# apollo3 register map
Vendor: Ambiq Micro; Series: Apollo; File version: 1.0
CPU: CM4 r1p0, little endian, MPU, FPU, 3 interrupt priority bits
Registers are 32-bit, read-write, reset 0x0 unless marked. A register's access mark holds for its fields unless they carry their own. Offsets are from the block's base; [hi:lo] are bit positions; {n}, {i} and the like mark numbered series; 'fields as' and 'values as' point back to an identical list.

## CTIMER (part 2 of 3) — Counter/Timer
Base 0x40008000
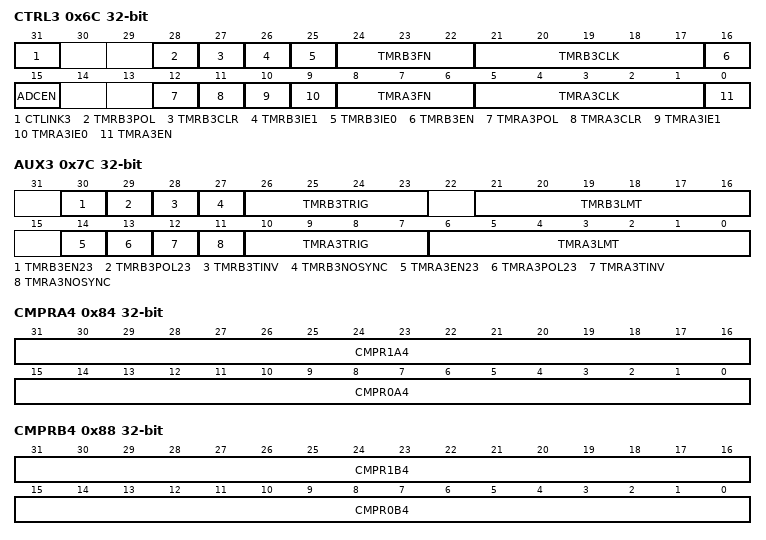
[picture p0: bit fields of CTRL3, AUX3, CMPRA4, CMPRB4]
0x6C CTRL3 — Counter/Timer Control
  [31] CTLINK3 — Counter/Timer A3/B3 Link bit.
    0=TWO_16BIT_TIMERS (Use A3/B3 timers as two independent 16-bit timers (default). value.); 1=32BIT_TIMER (Link A3/B3 timers into a single 32-bit timer. value.)
  [28] TMRB3POL — Counter/Timer B3 output polarity.
    0=NORMAL (The polarity of the TMRPINB3 pin is the same as the timer output. value.); 1=INVERTED (The polarity of the TMRPINB3 pin is the inverse of the timer output. value.)
  [27] TMRB3CLR — Counter/Timer B3 Clear bit.
    0=RUN (Allow counter/timer B3 to run value.); 1=CLEAR (Holds counter/timer B3 at 0x0000. value.)
  [26] TMRB3IE1 — Counter/Timer B3 Interrupt Enable bit for COMPR1.
    0=DIS (Disable counter/timer B3 from generating an interrupt based on COMPR1. value.); 1=EN (Enable counter/timer B3 to generate an interrupt based on COMPR1. value.)
  [25] TMRB3IE0 — Counter/Timer B3 Interrupt Enable bit for COMPR0.
    0=DIS (Disable counter/timer B3 from generating an interrupt based on COMPR0. value.); 1=EN (Enable counter/timer B3 to generate an interrupt based on COMPR0 value.)
  [24:22] TMRB3FN — Counter/Timer B3 Function Select.
    0=SINGLECOUNT (Single count (output toggles and sticks). Count to CMPR0B3, stop. value.); 1=REPEATEDCOUNT (Repeated count (periodic 1-clock-cycle-wide pulses). Count to CMPR0B3, restart. value.); 2=PULSE_ONCE (Pulse once (aka one-shot). Count to CMPR0B3, assert, count to CMPR1B3, deassert, stop. value.); 3=PULSE_CONT (Pulse continously. Count to CMPR0B3, assert, count to CMPR1B3, deassert, restart. value.); 4=SINGLEPATTERN (Single pattern. value.); 5=REPEATPATTERN (Repeated pattern. value.); 6=CONTINUOUS (Continuous run (aka Free Run). Count continuously. value.); 7=ALTPWN (Alternate PWM value.)
  [21:17] TMRB3CLK — Counter/Timer B3 Clock Select.
    0=TMRPIN (Clock source is TMRPINB. value.); 1=HFRC_DIV4 (Clock source is the HFRC / 4 value.); 2=HFRC_DIV16 (Clock source is HFRC / 16 value.); 3=HFRC_DIV256 (Clock source is HFRC / 256 value.); 4=HFRC_DIV1024 (Clock source is HFRC / 1024 value.); 5=HFRC_DIV4K (Clock source is HFRC / 4096 value.); 6=XT (Clock source is the XT (uncalibrated). value.); 7=XT_DIV2 (Clock source is XT / 2 value.); 8=XT_DIV16 (Clock source is XT / 16 value.); 9=XT_DIV128 (Clock source is XT / 128 value.); 10=LFRC_DIV2 (Clock source is LFRC / 2 value.); 11=LFRC_DIV32 (Clock source is LFRC / 32 value.); 12=LFRC_DIV1K (Clock source is LFRC / 1024 value.); 13=LFRC (Clock source is LFRC value.); 14=RTC_100HZ (Clock source is 100 Hz from the current RTC oscillator. value.); 15=HCLK (Clock source is HCLK. value.); 16=XT_DIV4 (Clock source is XT / 4 value.); 17=XT_DIV8 (Clock source is XT / 8 value.); 18=XT_DIV32 (Clock source is XT / 32 value.); 20=CTMRA3 (Clock source is CTIMERA3 OUT. value.); 21=CTMRA2 (Clock source is CTIMERA2 OUT. value.); 22=CTMRB2 (Clock source is CTIMERB2 OUT. value.); 23=CTMRA4 (Clock source is CTIMERA4 OUT. value.); 24=CTMRB4 (Clock source is CTIMERB4 OUT. value.); 25=CTMRB0 (Clock source is CTIMERB0 OUT. value.); 26=CTMRB1 (Clock source is CTIMERB1 OUT. value.); 27=CTMRB5 (Clock source is CTIMERB5 OUT. value.); 28=CTMRB6 (Clock source is CTIMERB6 OUT. value.); 29=BUCKBLE (Clock source is BLE buck converter TON pulses. value.); 30=BUCKB (Clock source is Memory buck converter TON pulses. value.); 31=BUCKA (Clock source is CPU buck converter TON pulses. value.)
  [16] TMRB3EN — Counter/Timer B3 Enable bit.
    0=DIS (Counter/Timer B3 Disable. value.); 1=EN (Counter/Timer B3 Enable. value.)
  [15] ADCEN — Special Timer A3 enable for ADC function.
  [12] TMRA3POL — Counter/Timer A3 output polarity.
    0=NORMAL (The polarity of the TMRPINA3 pin is the same as the timer output. value.); 1=INVERTED (The polarity of the TMRPINA3 pin is the inverse of the timer output. value.)
  [11] TMRA3CLR — Counter/Timer A3 Clear bit.
    0=RUN (Allow counter/timer A3 to run value.); 1=CLEAR (Holds counter/timer A3 at 0x0000. value.)
  [10] TMRA3IE1 — Counter/Timer A3 Interrupt Enable bit based on COMPR1.
    0=DIS (Disable counter/timer A3 from generating an interrupt based on COMPR1. value.); 1=EN (Enable counter/timer A3 to generate an interrupt based on COMPR1. value.)
  [9] TMRA3IE0 — Counter/Timer A3 Interrupt Enable bit based on COMPR0.
    0=DIS (Disable counter/timer A3 from generating an interrupt based on COMPR0. value.); 1=EN (Enable counter/timer A3 to generate an interrupt based on COMPR0. value.)
  [8:6] TMRA3FN — Counter/Timer A3 Function Select.
    0=SINGLECOUNT (Single count (output toggles and sticks). Count to CMPR0A3, stop. value.); 1=REPEATEDCOUNT (Repeated count (periodic 1-clock-cycle-wide pulses). Count to CMPR0A3, restart. value.); 2=PULSE_ONCE (Pulse once (aka one-shot). Count to CMPR0A3, assert, count to CMPR1A3, deassert, stop. value.); 3=PULSE_CONT (Pulse continously. Count to CMPR0A3, assert, count to CMPR1A3, deassert, restart. value.); 4=SINGLEPATTERN (Single pattern. value.); 5=REPEATPATTERN (Repeated pattern. value.); 6=CONTINUOUS (Continuous run (aka Free Run). Count continuously. value.); 7=ALTPWN (Alternate PWM value.)
  [5:1] TMRA3CLK — Counter/Timer A3 Clock Select.
    0=TMRPIN (Clock source is TMRPINA. value.); 1=HFRC_DIV4 (Clock source is the HFRC / 4 value.); 2=HFRC_DIV16 (Clock source is HFRC / 16 value.); 3=HFRC_DIV256 (Clock source is HFRC / 256 value.); 4=HFRC_DIV1024 (Clock source is HFRC / 1024 value.); 5=HFRC_DIV4K (Clock source is HFRC / 4096 value.); 6=XT (Clock source is the XT (uncalibrated). value.); 7=XT_DIV2 (Clock source is XT / 2 value.); 8=XT_DIV16 (Clock source is XT / 16 value.); 9=XT_DIV128 (Clock source is XT / 128 value.); 10=LFRC_DIV2 (Clock source is LFRC / 2 value.); 11=LFRC_DIV32 (Clock source is LFRC / 32 value.); 12=LFRC_DIV1K (Clock source is LFRC / 1024 value.); 13=LFRC (Clock source is LFRC value.); 14=RTC_100HZ (Clock source is 100 Hz from the current RTC oscillator. value.); 15=HCLK (Clock source is HCLK. value.); 16=XT_DIV4 (Clock source is XT / 4 value.); 17=XT_DIV8 (Clock source is XT / 8 value.); 18=XT_DIV32 (Clock source is XT / 32 value.); 20=CTMRB3 (Clock source is CTIMERB3 OUT. value.); 21=CTMRA2 (Clock source is CTIMERA2 OUT. value.); 22=CTMRB2 (Clock source is CTIMERB2 OUT. value.); 23=CTMRA4 (Clock source is CTIMERA4 OUT. value.); 24=CTMRB4 (Clock source is CTIMERB4 OUT. value.); 25=CTMRB0 (Clock source is CTIMERB0 OUT. value.); 26=CTMRB1 (Clock source is CTIMERB1 OUT. value.); 27=CTMRB5 (Clock source is CTIMERB5 OUT. value.); 28=CTMRB6 (Clock source is CTIMERB6 OUT. value.); 29=BUCKBLE (Clock source is BLE buck converter TON pulses. value.); 30=BUCKB (Clock source is Memory buck converter TON pulses. value.); 31=BUCKA (Clock source is CPU buck converter TON pulses. value.)
  [0] TMRA3EN — Counter/Timer A3 Enable bit.
    0=DIS (Counter/Timer A3 Disable. value.); 1=EN (Counter/Timer A3 Enable. value.)
0x7C AUX3 — Counter/Timer Auxiliary
  [30] TMRB3EN23 — Counter/Timer B3 Upper compare enable.
    1=DIS (Disable enhanced functions. value.); 0=EN (Enable enhanced functions. value.)
  [29] TMRB3POL23 — Upper output polarity
    0=NORM (Upper output normal polarity value.); 1=INV (Upper output inverted polarity. value.)
  [28] TMRB3TINV — Counter/Timer B3 Invert on trigger.
    0=DIS (Disable invert on trigger value.); 1=EN (Enable invert on trigger value.)
  [27] TMRB3NOSYNC — Source clock synchronization control.
    0=DIS (Synchronization on source clock value.); 1=NOSYNC (No synchronization on source clock value.)
  [26:23] TMRB3TRIG — Counter/Timer B3 Trigger Select.
    0=DIS (Trigger source is disabled. value.); 1=A3OUT (Trigger source is CTIMERA3 OUT. value.); 2=B2OUT (Trigger source is CTIMERB2 OUT. value.); 3=A2OUT (Trigger source is CTIMERA2 OUT. value.); 4=A4OUT (Trigger source is CTIMERA4 OUT. value.); 5=B4OUT (Trigger source is CTIMERB4 OUT. value.); 6=A6OUT (Trigger source is CTIMERA6 OUT. value.); 7=B6OUT (Trigger source is CTIMERB6 OUT. value.); 8=B5OUT2 (Trigger source is CTIMERB5 OUT2. value.); 9=A5OUT2 (Trigger source is CTIMERA5 OUT2. value.); 10=A1OUT2 (Trigger source is CTIMERA1 OUT2. value.); 11=B1OUT2 (Trigger source is CTIMERB1 OUT2. value.); 12=A6OUT2DUAL (Trigger source is CTIMERA6 OUT2, dual edge. value.); 13=A7OUT2DUAL (Trigger source is CTIMERA7 OUT2, dual edge. value.); 14=B2OUT2DUAL (Trigger source is CTIMERB2 OUT2, dual edge. value.); 15=A2OUT2DUAL (Trigger source is CTIMERA2 OUT2, dual edge. value.)
  [21:16] TMRB3LMT — Counter/Timer B3 Pattern Limit Count.
  [14] TMRA3EN23 — Counter/Timer A3 Upper compare enable.
    values as TMRB3EN23
  [13] TMRA3POL23 — Counter/Timer A3 Upper output polarity
    values as TMRB3POL23
  [12] TMRA3TINV — Counter/Timer A3 Invert on trigger.
    values as TMRB3TINV
  [11] TMRA3NOSYNC — Source clock synchronization control.
    values as TMRB3NOSYNC
  [10:7] TMRA3TRIG — Counter/Timer A3 Trigger Select.
    0=DIS (Trigger source is disabled. value.); 1=B3OUT (Trigger source is CTIMERB3 OUT. value.); 2=B2OUT (Trigger source is CTIMERB2 OUT. value.); 3=A2OUT (Trigger source is CTIMERA2 OUT. value.); 4=A4OUT (Trigger source is CTIMERA4 OUT. value.); 5=B4OUT (Trigger source is CTIMERB4 OUT. value.); 6=A7OUT (Trigger source is CTIMERA7 OUT. value.); 7=B7OUT (Trigger source is CTIMERB7 OUT. value.); 8=B5OUT2 (Trigger source is CTIMERB5 OUT2. value.); 9=A5OUT2 (Trigger source is CTIMERA5 OUT2. value.); 10=A1OUT2 (Trigger source is CTIMERA1 OUT2. value.); 11=B1OUT2 (Trigger source is CTIMERB1 OUT2. value.); 12=A6OUT2DUAL (Trigger source is CTIMERA6 OUT2, dual edge. value.); 13=A7OUT2DUAL (Trigger source is CTIMERA7 OUT2, dual edge. value.); 14=B2OUT2DUAL (Trigger source is CTIMERB2 OUT2, dual edge. value.); 15=A2OUT2DUAL (Trigger source is CTIMERA2 OUT2, dual edge. value.)
  [6:0] TMRA3LMT — Counter/Timer A3 Pattern Limit Count.
0x84 CMPRA4 — Counter/Timer A4 Compare Registers
  [31:16] CMPR1A4 — Counter/Timer A4 Compare Register 1. Holds the upper limit for timer half A.
  [15:0] CMPR0A4 — Counter/Timer A4 Compare Register 0. Holds the lower limit for timer half A.
0x88 CMPRB4 — Counter/Timer B4 Compare Registers
  [31:16] CMPR1B4 — Counter/Timer B4 Compare Register 1. Holds the upper limit for timer half B.
  [15:0] CMPR0B4 — Counter/Timer B4 Compare Register 0. Holds the lower limit for timer half B.
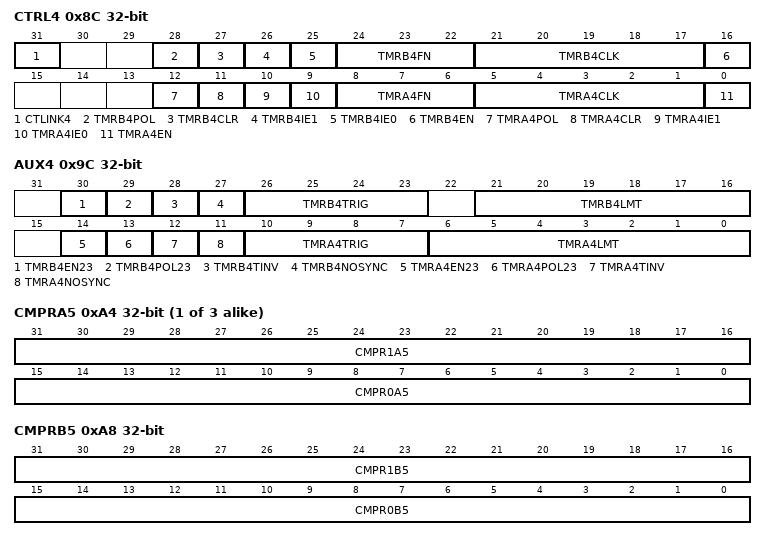
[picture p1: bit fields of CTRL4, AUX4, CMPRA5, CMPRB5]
0x8C CTRL4 — Counter/Timer Control
  [31] CTLINK4 — Counter/Timer A4/B4 Link bit.
    0=TWO_16BIT_TIMERS (Use A4/B4 timers as two independent 16-bit timers (default). value.); 1=32BIT_TIMER (Link A4/B4 timers into a single 32-bit timer. value.)
  [28] TMRB4POL — Counter/Timer B4 output polarity.
    0=NORMAL (The polarity of the TMRPINB4 pin is the same as the timer output. value.); 1=INVERTED (The polarity of the TMRPINB4 pin is the inverse of the timer output. value.)
  [27] TMRB4CLR — Counter/Timer B4 Clear bit.
    0=RUN (Allow counter/timer B4 to run value.); 1=CLEAR (Holds counter/timer B4 at 0x0000. value.)
  [26] TMRB4IE1 — Counter/Timer B4 Interrupt Enable bit for COMPR1.
    0=DIS (Disable counter/timer B4 from generating an interrupt based on COMPR1. value.); 1=EN (Enable counter/timer B4 to generate an interrupt based on COMPR1. value.)
  [25] TMRB4IE0 — Counter/Timer B4 Interrupt Enable bit for COMPR0.
    0=DIS (Disable counter/timer B4 from generating an interrupt based on COMPR0. value.); 1=EN (Enable counter/timer B4 to generate an interrupt based on COMPR0 value.)
  [24:22] TMRB4FN — Counter/Timer B4 Function Select.
    0=SINGLECOUNT (Single count (output toggles and sticks). Count to CMPR0B4, stop. value.); 1=REPEATEDCOUNT (Repeated count (periodic 1-clock-cycle-wide pulses). Count to CMPR0B4, restart. value.); 2=PULSE_ONCE (Pulse once (aka one-shot). Count to CMPR0B4, assert, count to CMPR1B4, deassert, stop. value.); 3=PULSE_CONT (Pulse continously. Count to CMPR0B4, assert, count to CMPR1B4, deassert, restart. value.); 4=SINGLEPATTERN (Single pattern. value.); 5=REPEATPATTERN (Repeated pattern. value.); 6=CONTINUOUS (Continuous run (aka Free Run). Count continuously. value.); 7=ALTPWN (Alternate PWM value.)
  [21:17] TMRB4CLK — Counter/Timer B4 Clock Select.
    0=TMRPIN (Clock source is TMRPINB. value.); 1=HFRC_DIV4 (Clock source is the HFRC / 4 value.); 2=HFRC_DIV16 (Clock source is HFRC / 16 value.); 3=HFRC_DIV256 (Clock source is HFRC / 256 value.); 4=HFRC_DIV1024 (Clock source is HFRC / 1024 value.); 5=HFRC_DIV4K (Clock source is HFRC / 4096 value.); 6=XT (Clock source is the XT (uncalibrated). value.); 7=XT_DIV2 (Clock source is XT / 2 value.); 8=XT_DIV16 (Clock source is XT / 16 value.); 9=XT_DIV128 (Clock source is XT / 128 value.); 10=LFRC_DIV2 (Clock source is LFRC / 2 value.); 11=LFRC_DIV32 (Clock source is LFRC / 32 value.); 12=LFRC_DIV1K (Clock source is LFRC / 1024 value.); 13=LFRC (Clock source is LFRC value.); 14=RTC_100HZ (Clock source is 100 Hz from the current RTC oscillator. value.); 15=HCLK (Clock source is HCLK. value.); 16=XT_DIV4 (Clock source is XT / 4 value.); 17=XT_DIV8 (Clock source is XT / 8 value.); 18=XT_DIV32 (Clock source is XT / 32 value.); 20=CTMRA4 (Clock source is CTIMERA4 OUT. value.); 21=CTMRA1 (Clock source is CTIMERA1 OUT. value.); 22=CTMRB1 (Clock source is CTIMERB1 OUT. value.); 23=CTMRA5 (Clock source is CTIMERA5 OUT. value.); 24=CTMRB5 (Clock source is CTIMERB5 OUT. value.); 25=CTMRB0 (Clock source is CTIMERB0 OUT. value.); 26=CTMRB2 (Clock source is CTIMERB2 OUT. value.); 27=CTMRB3 (Clock source is CTIMERB3 OUT. value.); 28=CTMRB6 (Clock source is CTIMERB6 OUT. value.); 29=BUCKBLE (Clock source is BLE buck converter TON pulses. value.); 30=BUCKB (Clock source is Memory buck converter TON pulses. value.); 31=BUCKA (Clock source is CPU buck converter TON pulses. value.)
  [16] TMRB4EN — Counter/Timer B4 Enable bit.
    0=DIS (Counter/Timer B4 Disable. value.); 1=EN (Counter/Timer B4 Enable. value.)
  [12] TMRA4POL — Counter/Timer A4 output polarity.
    0=NORMAL (The polarity of the TMRPINA4 pin is the same as the timer output. value.); 1=INVERTED (The polarity of the TMRPINA4 pin is the inverse of the timer output. value.)
  [11] TMRA4CLR — Counter/Timer A4 Clear bit.
    0=RUN (Allow counter/timer A4 to run value.); 1=CLEAR (Holds counter/timer A4 at 0x0000. value.)
  [10] TMRA4IE1 — Counter/Timer A4 Interrupt Enable bit based on COMPR1.
    0=DIS (Disable counter/timer A4 from generating an interrupt based on COMPR1. value.); 1=EN (Enable counter/timer A4 to generate an interrupt based on COMPR1. value.)
  [9] TMRA4IE0 — Counter/Timer A4 Interrupt Enable bit based on COMPR0.
    0=DIS (Disable counter/timer A4 from generating an interrupt based on COMPR0. value.); 1=EN (Enable counter/timer A4 to generate an interrupt based on COMPR0. value.)
  [8:6] TMRA4FN — Counter/Timer A4 Function Select.
    0=SINGLECOUNT (Single count (output toggles and sticks). Count to CMPR0A4, stop. value.); 1=REPEATEDCOUNT (Repeated count (periodic 1-clock-cycle-wide pulses). Count to CMPR0A4, restart. value.); 2=PULSE_ONCE (Pulse once (aka one-shot). Count to CMPR0A4, assert, count to CMPR1A4, deassert, stop. value.); 3=PULSE_CONT (Pulse continously. Count to CMPR0A4, assert, count to CMPR1A4, deassert, restart. value.); 4=SINGLEPATTERN (Single pattern. value.); 5=REPEATPATTERN (Repeated pattern. value.); 6=CONTINUOUS (Continuous run (aka Free Run). Count continuously. value.); 7=ALTPWN (Alternate PWM value.)
  [5:1] TMRA4CLK — Counter/Timer A4 Clock Select.
    0=TMRPIN (Clock source is TMRPINA. value.); 1=HFRC_DIV4 (Clock source is the HFRC / 4 value.); 2=HFRC_DIV16 (Clock source is HFRC / 16 value.); 3=HFRC_DIV256 (Clock source is HFRC / 256 value.); 4=HFRC_DIV1024 (Clock source is HFRC / 1024 value.); 5=HFRC_DIV4K (Clock source is HFRC / 4096 value.); 6=XT (Clock source is the XT (uncalibrated). value.); 7=XT_DIV2 (Clock source is XT / 2 value.); 8=XT_DIV16 (Clock source is XT / 16 value.); 9=XT_DIV128 (Clock source is XT / 128 value.); 10=LFRC_DIV2 (Clock source is LFRC / 2 value.); 11=LFRC_DIV32 (Clock source is LFRC / 32 value.); 12=LFRC_DIV1K (Clock source is LFRC / 1024 value.); 13=LFRC (Clock source is LFRC value.); 14=RTC_100HZ (Clock source is 100 Hz from the current RTC oscillator. value.); 15=HCLK_DIV4 (Clock source is HCLK / 4. value.); 16=XT_DIV4 (Clock source is XT / 4 value.); 17=XT_DIV8 (Clock source is XT / 8 value.); 18=XT_DIV32 (Clock source is XT / 32 value.); 20=CTMRB4 (Clock source is CTIMERB4 OUT. value.); 21=CTMRA1 (Clock source is CTIMERA1 OUT. value.); 22=CTMRB1 (Clock source is CTIMERB1 OUT. value.); 23=CTMRA5 (Clock source is CTIMERA5 OUT. value.); 24=CTMRB5 (Clock source is CTIMERB5 OUT. value.); 25=CTMRB0 (Clock source is CTIMERB0 OUT. value.); 26=CTMRB2 (Clock source is CTIMERB2 OUT. value.); 27=CTMRB3 (Clock source is CTIMERB3 OUT. value.); 28=CTMRB6 (Clock source is CTIMERB6 OUT. value.); 29=BUCKBLE (Clock source is BLE buck converter TON pulses. value.); 30=BUCKB (Clock source is Memory buck converter TON pulses. value.); 31=BUCKA (Clock source is CPU buck converter TON pulses. value.)
  [0] TMRA4EN — Counter/Timer A4 Enable bit.
    0=DIS (Counter/Timer A4 Disable. value.); 1=EN (Counter/Timer A4 Enable. value.)
0x9C AUX4 — Counter/Timer Auxiliary
  [30] TMRB4EN23 — Counter/Timer B4 Upper compare enable.
    values as AUX3.TMRB3EN23
  [29] TMRB4POL23 — Upper output polarity
    values as AUX3.TMRB3POL23
  [28] TMRB4TINV — Counter/Timer B4 Invert on trigger.
    values as AUX3.TMRB3TINV
  [27] TMRB4NOSYNC — Source clock synchronization control.
    values as AUX3.TMRB3NOSYNC
  [26:23] TMRB4TRIG — Counter/Timer B4 Trigger Select.
    0=DIS (Trigger source is disabled. value.); 1=A4OUT (Trigger source is CTIMERA4 OUT. value.); 2=B3OUT (Trigger source is CTIMERB3 OUT. value.); 3=A3OUT (Trigger source is CTIMERA3 OUT. value.); 4=A7OUT (Trigger source is CTIMERA7 OUT. value.); 5=B7OUT (Trigger source is CTIMERB7 OUT. value.); 6=A1OUT (Trigger source is CTIMERA1 OUT. value.); 7=B1OUT (Trigger source is CTIMERB1 OUT. value.); 8=B3OUT2 (Trigger source is CTIMERB3 OUT2. value.); 9=A3OUT2 (Trigger source is CTIMERA3 OUT2. value.); 10=A1OUT2 (Trigger source is CTIMERA1 OUT2. value.); 11=B1OUT2 (Trigger source is CTIMERB1 OUT2. value.); 12=A6OUT2DUAL (Trigger source is CTIMERA6 OUT2, dual edge. value.); 13=A7OUT2DUAL (Trigger source is CTIMERA7 OUT2, dual edge. value.); 14=B5OUT2DUAL (Trigger source is CTIMERB5 OUT2, dual edge. value.); 15=A5OUT2DUAL (Trigger source is CTIMERA5 OUT2, dual edge. value.)
  [21:16] TMRB4LMT — Counter/Timer B4 Pattern Limit Count.
  [14] TMRA4EN23 — Counter/Timer A4 Upper compare enable.
    values as AUX3.TMRB3EN23
  [13] TMRA4POL23 — Counter/Timer A4 Upper output polarity
    values as AUX3.TMRB3POL23
  [12] TMRA4TINV — Counter/Timer A4 Invert on trigger.
    values as AUX3.TMRB3TINV
  [11] TMRA4NOSYNC — Source clock synchronization control.
    values as AUX3.TMRB3NOSYNC
  [10:7] TMRA4TRIG — Counter/Timer A4 Trigger Select.
    0=DIS (Trigger source is disabled. value.); 1=B4OUT (Trigger source is CTIMERB4 OUT. value.); 2=B3OUT (Trigger source is CTIMERB3 OUT. value.); 3=A3OUT (Trigger source is CTIMERA3 OUT. value.); 4=A6OUT (Trigger source is CTIMERA6 OUT. value.); 5=B6OUT (Trigger source is CTIMERB6 OUT. value.); 6=A2OUT (Trigger source is CTIMERA2 OUT. value.); 7=B2OUT (Trigger source is CTIMERB2 OUT. value.); 8=B3OUT2 (Trigger source is CTIMERB3 OUT2. value.); 9=A3OUT2 (Trigger source is CTIMERA3 OUT2. value.); 10=A1OUT2 (Trigger source is CTIMERA1 OUT2. value.); 11=B1OUT2 (Trigger source is CTIMERB1 OUT2. value.); 12=A6OUT2DUAL (Trigger source is CTIMERA6 OUT2, dual edge. value.); 13=A7OUT2DUAL (Trigger source is CTIMERA7 OUT2, dual edge. value.); 14=B5OUT2DUAL (Trigger source is CTIMERB5 OUT2, dual edge. value.); 15=A5OUT2DUAL (Trigger source is CTIMERA5 OUT2, dual edge. value.)
  [6:0] TMRA4LMT — Counter/Timer A4 Pattern Limit Count.
{0x4+0x20*i} CMPRA{i} (i=5..7) — Counter/Timer A{i} Compare Registers
  [31:16] CMPR1A{i} — Counter/Timer A{i} Compare Register 1.
  [15:0] CMPR0A{i} — Counter/Timer A{i} Compare Register 0.
0xA8 CMPRB5 — Counter/Timer B5 Compare Registers
  [31:16] CMPR1B5 — Counter/Timer B5 Compare Register 1.
  [15:0] CMPR0B5 — Counter/Timer B5 Compare Register 0.
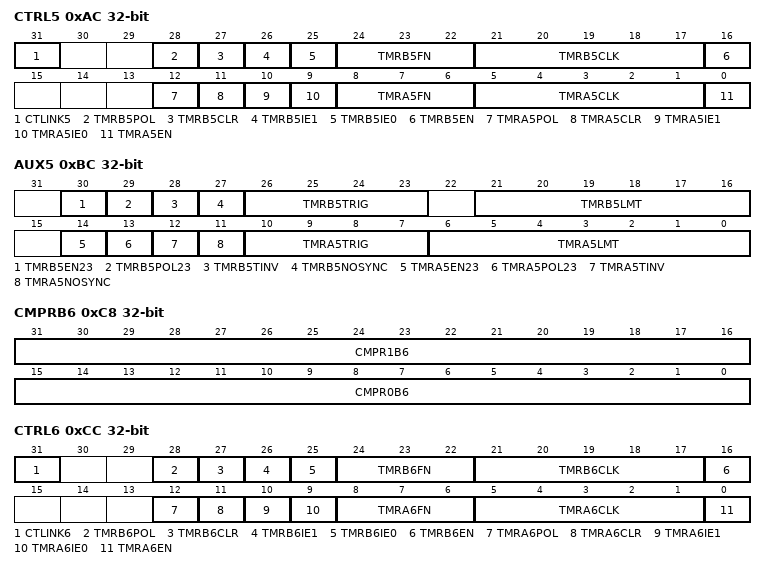
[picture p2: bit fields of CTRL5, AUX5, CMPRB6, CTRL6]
0xAC CTRL5 — Counter/Timer Control
  [31] CTLINK5 — Counter/Timer A5/B5 Link bit.
    0=TWO_16BIT_TIMERS (Use A5/B5 timers as two independent 16-bit timers (default). value.); 1=32BIT_TIMER (Link A5/B5 timers into a single 32-bit timer. value.)
  [28] TMRB5POL — Counter/Timer B5 output polarity.
    0=NORMAL (The polarity of the TMRPINB5 pin is the same as the timer output. value.); 1=INVERTED (The polarity of the TMRPINB5 pin is the inverse of the timer output. value.)
  [27] TMRB5CLR — Counter/Timer B5 Clear bit.
    0=RUN (Allow counter/timer B5 to run value.); 1=CLEAR (Holds counter/timer B5 at 0x0000. value.)
  [26] TMRB5IE1 — Counter/Timer B5 Interrupt Enable bit for COMPR1.
    0=DIS (Disable counter/timer B5 from generating an interrupt based on COMPR1. value.); 1=EN (Enable counter/timer B5 to generate an interrupt based on COMPR1. value.)
  [25] TMRB5IE0 — Counter/Timer B5 Interrupt Enable bit for COMPR0.
    0=DIS (Disable counter/timer B5 from generating an interrupt based on COMPR0. value.); 1=EN (Enable counter/timer B5 to generate an interrupt based on COMPR0 value.)
  [24:22] TMRB5FN — Counter/Timer B5 Function Select.
    0=SINGLECOUNT (Single count (output toggles and sticks). Count to CMPR0B5, stop. value.); 1=REPEATEDCOUNT (Repeated count (periodic 1-clock-cycle-wide pulses). Count to CMPR0B5, restart. value.); 2=PULSE_ONCE (Pulse once (aka one-shot). Count to CMPR0B5, assert, count to CMPR1B5, deassert, stop. value.); 3=PULSE_CONT (Pulse continously. Count to CMPR0B5, assert, count to CMPR1B5, deassert, restart. value.); 4=SINGLEPATTERN (Single pattern. value.); 5=REPEATPATTERN (Repeated pattern. value.); 6=CONTINUOUS (Continuous run (aka Free Run). Count continuously. value.); 7=ALTPWN (Alternate PWM value.)
  [21:17] TMRB5CLK — Counter/Timer B5 Clock Select.
    0=TMRPIN (Clock source is TMRPINB. value.); 1=HFRC_DIV4 (Clock source is the HFRC / 4 value.); 2=HFRC_DIV16 (Clock source is HFRC / 16 value.); 3=HFRC_DIV256 (Clock source is HFRC / 256 value.); 4=HFRC_DIV1024 (Clock source is HFRC / 1024 value.); 5=HFRC_DIV4K (Clock source is HFRC / 4096 value.); 6=XT (Clock source is the XT (uncalibrated). value.); 7=XT_DIV2 (Clock source is XT / 2 value.); 8=XT_DIV16 (Clock source is XT / 16 value.); 9=XT_DIV128 (Clock source is XT / 128 value.); 10=LFRC_DIV2 (Clock source is LFRC / 2 value.); 11=LFRC_DIV32 (Clock source is LFRC / 32 value.); 12=LFRC_DIV1K (Clock source is LFRC / 1024 value.); 13=LFRC (Clock source is LFRC value.); 14=RTC_100HZ (Clock source is 100 Hz from the current RTC oscillator. value.); 15=HCLK (Clock source is HCLK. value.); 16=XT_DIV4 (Clock source is XT / 4 value.); 17=XT_DIV8 (Clock source is XT / 8 value.); 18=XT_DIV32 (Clock source is XT / 32 value.); 20=CTMRA5 (Clock source is CTIMERA5 OUT. value.); 21=CTMRA0 (Clock source is CTIMERA0 OUT. value.); 22=CTMRB0 (Clock source is CTIMERB0 OUT. value.); 23=CTMRA6 (Clock source is CTIMERA6 OUT. value.); 24=CTMRB6 (Clock source is CTIMERB6 OUT. value.); {v}=CTMRB{v-24} (Clock source is CTIMERB{v-24} OUT. value.) (v=25..28); 29=BUCKBLE (Clock source is BLE buck converter TON pulses. value.); 30=BUCKB (Clock source is Memory buck converter TON pulses. value.); 31=BUCKA (Clock source is CPU buck converter TON pulses. value.)
  [16] TMRB5EN — Counter/Timer B5 Enable bit.
    0=DIS (Counter/Timer B5 Disable. value.); 1=EN (Counter/Timer B5 Enable. value.)
  [12] TMRA5POL — Counter/Timer A5 output polarity.
    0=NORMAL (The polarity of the TMRPINA5 pin is the same as the timer output. value.); 1=INVERTED (The polarity of the TMRPINA5 pin is the inverse of the timer output. value.)
  [11] TMRA5CLR — Counter/Timer A5 Clear bit.
    0=RUN (Allow counter/timer A5 to run value.); 1=CLEAR (Holds counter/timer A5 at 0x0000. value.)
  [10] TMRA5IE1 — Counter/Timer A5 Interrupt Enable bit based on COMPR1.
    0=DIS (Disable counter/timer A5 from generating an interrupt based on COMPR1. value.); 1=EN (Enable counter/timer A5 to generate an interrupt based on COMPR1. value.)
  [9] TMRA5IE0 — Counter/Timer A5 Interrupt Enable bit based on COMPR0.
    0=DIS (Disable counter/timer A5 from generating an interrupt based on COMPR0. value.); 1=EN (Enable counter/timer A5 to generate an interrupt based on COMPR0. value.)
  [8:6] TMRA5FN — Counter/Timer A5 Function Select.
    0=SINGLECOUNT (Single count (output toggles and sticks). Count to CMPR0A5, stop. value.); 1=REPEATEDCOUNT (Repeated count (periodic 1-clock-cycle-wide pulses). Count to CMPR0A5, restart. value.); 2=PULSE_ONCE (Pulse once (aka one-shot). Count to CMPR0A5, assert, count to CMPR1A5, deassert, stop. value.); 3=PULSE_CONT (Pulse continously. Count to CMPR0A5, assert, count to CMPR1A5, deassert, restart. value.); 4=SINGLEPATTERN (Single pattern. value.); 5=REPEATPATTERN (Repeated pattern. value.); 6=CONTINUOUS (Continuous run (aka Free Run). Count continuously. value.); 7=ALTPWN (Alternate PWM value.)
  [5:1] TMRA5CLK — Counter/Timer A5 Clock Select.
    0=TMRPIN (Clock source is TMRPINA. value.); 1=HFRC_DIV4 (Clock source is the HFRC / 4 value.); 2=HFRC_DIV16 (Clock source is HFRC / 16 value.); 3=HFRC_DIV256 (Clock source is HFRC / 256 value.); 4=HFRC_DIV1024 (Clock source is HFRC / 1024 value.); 5=HFRC_DIV4K (Clock source is HFRC / 4096 value.); 6=XT (Clock source is the XT (uncalibrated). value.); 7=XT_DIV2 (Clock source is XT / 2 value.); 8=XT_DIV16 (Clock source is XT / 16 value.); 9=XT_DIV128 (Clock source is XT / 128 value.); 10=LFRC_DIV2 (Clock source is LFRC / 2 value.); 11=LFRC_DIV32 (Clock source is LFRC / 32 value.); 12=LFRC_DIV1K (Clock source is LFRC / 1024 value.); 13=LFRC (Clock source is LFRC value.); 14=RTC_100HZ (Clock source is 100 Hz from the current RTC oscillator. value.); 15=HCLK (Clock source is HCLK. value.); 16=XT_DIV4 (Clock source is XT / 4 value.); 17=XT_DIV8 (Clock source is XT / 8 value.); 18=XT_DIV32 (Clock source is XT / 32 value.); 20=CTMRB5 (Clock source is CTIMERB5 OUT. value.); 21=CTMRA0 (Clock source is CTIMERA0 OUT. value.); 22=CTMRB0 (Clock source is CTIMERB0 OUT. value.); 23=CTMRA6 (Clock source is CTIMERA6 OUT. value.); 24=CTMRB6 (Clock source is CTIMERB6 OUT. value.); {v}=CTMRB{v-24} (Clock source is CTIMERB{v-24} OUT. value.) (v=25..28); 29=BUCKBLE (Clock source is BLE buck converter TON pulses. value.); 30=BUCKB (Clock source is Memory buck converter TON pulses. value.); 31=BUCKA (Clock source is CPU buck converter TON pulses. value.)
  [0] TMRA5EN — Counter/Timer A5 Enable bit.
    0=DIS (Counter/Timer A5 Disable. value.); 1=EN (Counter/Timer A5 Enable. value.)
0xBC AUX5 — Counter/Timer Auxiliary
  [30] TMRB5EN23 — Counter/Timer B5 Upper compare enable.
    values as AUX3.TMRB3EN23
  [29] TMRB5POL23 — Upper output polarity
    values as AUX3.TMRB3POL23
  [28] TMRB5TINV — Counter/Timer B5 Invert on trigger.
    values as AUX3.TMRB3TINV
  [27] TMRB5NOSYNC — Source clock synchronization control.
    values as AUX3.TMRB3NOSYNC
  [26:23] TMRB5TRIG — Counter/Timer B5 Trigger Select.
    0=DIS (Trigger source is disabled. value.); 1=A5OUT (Trigger source is CTIMERA5 OUT. value.); 2=B3OUT (Trigger source is CTIMERB3 OUT. value.); 3=A3OUT (Trigger source is CTIMERA3 OUT. value.); 4=A6OUT (Trigger source is CTIMERA6 OUT. value.); 5=B6OUT (Trigger source is CTIMERB6 OUT. value.); 6=A1OUT (Trigger source is CTIMERA1 OUT. value.); 7=B1OUT (Trigger source is CTIMERB1 OUT. value.); 8=B3OUT2 (Trigger source is CTIMERB3 OUT2. value.); 9=A3OUT2 (Trigger source is CTIMERA3 OUT2. value.); 10=A0OUT2 (Trigger source is CTIMERA0 OUT2. value.); 11=B0OUT2 (Trigger source is CTIMERB0 OUT2. value.); 12=A6OUT2DUAL (Trigger source is CTIMERA6 OUT2, dual edge. value.); 13=A7OUT2DUAL (Trigger source is CTIMERA7 OUT2, dual edge. value.); 14=B4OUT2DUAL (Trigger source is CTIMERB4 OUT2, dual edge. value.); 15=A4OUT2DUAL (Trigger source is CTIMERA4 OUT2, dual edge. value.)
  [21:16] TMRB5LMT — Counter/Timer B5 Pattern Limit Count.
  [14] TMRA5EN23 — Counter/Timer A5 Upper compare enable.
    values as AUX3.TMRB3EN23
  [13] TMRA5POL23 — Counter/Timer A5 Upper output polarity
    0=NORMAL (Upper output normal polarity value.); 1=INV (Upper output inverted polarity. value.)
  [12] TMRA5TINV — Counter/Timer A5 Invert on trigger.
    values as AUX3.TMRB3TINV
  [11] TMRA5NOSYNC — Source clock synchronization control.
    values as AUX3.TMRB3NOSYNC
  [10:7] TMRA5TRIG — Counter/Timer A5 Trigger Select.
    0=DIS (Trigger source is disabled. value.); 1=B5OUT (Trigger source is CTIMERB5 OUT. value.); 2=B3OUT (Trigger source is CTIMERB3 OUT. value.); 3=A3OUT (Trigger source is CTIMERA3 OUT. value.); 4=A4OUT (Trigger source is CTIMERA4 OUT. value.); 5=B4OUT (Trigger source is CTIMERB4 OUT. value.); 6=A2OUT (Trigger source is CTIMERA2 OUT. value.); 7=B2OUT (Trigger source is CTIMERB2 OUT. value.); 8=B3OUT2 (Trigger source is CTIMERB3 OUT2. value.); 9=A3OUT2 (Trigger source is CTIMERA3 OUT2. value.); 10=A0OUT2 (Trigger source is CTIMERA0 OUT2. value.); 11=B0OUT2 (Trigger source is CTIMERB0 OUT2. value.); 12=A6OUT2DUAL (Trigger source is CTIMERA6 OUT2, dual edge. value.); 13=A7OUT2DUAL (Trigger source is CTIMERA7 OUT2, dual edge. value.); 14=B4OUT2DUAL (Trigger source is CTIMERB4 OUT2, dual edge. value.); 15=A4OUT2DUAL (Trigger source is CTIMERA4 OUT2, dual edge. value.)
  [6:0] TMRA5LMT — Counter/Timer A5 Pattern Limit Count.
0xC8 CMPRB6 — Counter/Timer B6 Compare Registers
  [31:16] CMPR1B6 — Counter/Timer B6 Compare Register 1.
  [15:0] CMPR0B6 — Counter/Timer B6 Compare Register 0.
0xCC CTRL6 — Counter/Timer Control
  [31] CTLINK6 — Counter/Timer A6/B6 Link bit.
    0=TWO_16BIT_TIMERS (Use A6/B6 timers as two independent 16-bit timers (default). value.); 1=32BIT_TIMER (Link A6/B6 timers into a single 32-bit timer. value.)
  [28] TMRB6POL — Counter/Timer B6 output polarity.
    0=NORMAL (The polarity of the TMRPINB6 pin is the same as the timer output. value.); 1=INVERTED (The polarity of the TMRPINB6 pin is the inverse of the timer output. value.)
  [27] TMRB6CLR — Counter/Timer B6 Clear bit.
    0=RUN (Allow counter/timer B6 to run value.); 1=CLEAR (Holds counter/timer B6 at 0x0000. value.)
  [26] TMRB6IE1 — Counter/Timer B6 Interrupt Enable bit for COMPR1.
    0=DIS (Disable counter/timer B6 from generating an interrupt based on COMPR1. value.); 1=EN (Enable counter/timer B6 to generate an interrupt based on COMPR1. value.)
  [25] TMRB6IE0 — Counter/Timer B6 Interrupt Enable bit for COMPR0.
    0=DIS (Disable counter/timer B6 from generating an interrupt based on COMPR0. value.); 1=EN (Enable counter/timer B6 to generate an interrupt based on COMPR0 value.)
  [24:22] TMRB6FN — Counter/Timer B6 Function Select.
    0=SINGLECOUNT (Single count (output toggles and sticks). Count to CMPR0B6, stop. value.); 1=REPEATEDCOUNT (Repeated count (periodic 1-clock-cycle-wide pulses). Count to CMPR0B6, restart. value.); 2=PULSE_ONCE (Pulse once (aka one-shot). Count to CMPR0B6, assert, count to CMPR1B6, deassert, stop. value.); 3=PULSE_CONT (Pulse continously. Count to CMPR0B6, assert, count to CMPR1B6, deassert, restart. value.); 4=SINGLEPATTERN (Single pattern. value.); 5=REPEATPATTERN (Repeated pattern. value.); 6=CONTINUOUS (Continuous run (aka Free Run). Count continuously. value.); 7=ALTPWN (Alternate PWM value.)
  [21:17] TMRB6CLK — Counter/Timer B6 Clock Select.
    0=TMRPIN (Clock source is TMRPINB. value.); 1=HFRC_DIV4 (Clock source is the HFRC / 4 value.); 2=HFRC_DIV16 (Clock source is HFRC / 16 value.); 3=HFRC_DIV256 (Clock source is HFRC / 256 value.); 4=HFRC_DIV1024 (Clock source is HFRC / 1024 value.); 5=HFRC_DIV4K (Clock source is HFRC / 4096 value.); 6=XT (Clock source is the XT (uncalibrated). value.); 7=XT_DIV2 (Clock source is XT / 2 value.); 8=XT_DIV16 (Clock source is XT / 16 value.); 9=XT_DIV128 (Clock source is XT / 128 value.); 10=LFRC_DIV2 (Clock source is LFRC / 2 value.); 11=LFRC_DIV32 (Clock source is LFRC / 32 value.); 12=LFRC_DIV1K (Clock source is LFRC / 1024 value.); 13=LFRC (Clock source is LFRC value.); 14=RTC_100HZ (Clock source is 100 Hz from the current RTC oscillator. value.); 15=HCLK (Clock source is HCLK. value.); 16=XT_DIV4 (Clock source is XT / 4 value.); 17=XT_DIV8 (Clock source is XT / 8 value.); 18=XT_DIV32 (Clock source is XT / 32 value.); 20=CTMRA6 (Clock source is CTIMERA6 OUT. value.); 21=CTMRA3 (Clock source is CTIMERA3 OUT. value.); 22=CTMRB3 (Clock source is CTIMERB3 OUT. value.); 23=CTMRA7 (Clock source is CTIMERA7 OUT. value.); 24=CTMRB7 (Clock source is CTIMERB7 OUT. value.); 25=CTMRB0 (Clock source is CTIMERB0 OUT. value.); 26=CTMRB1 (Clock source is CTIMERB1 OUT. value.); 27=CTMRB2 (Clock source is CTIMERB2 OUT. value.); 28=CTMRB4 (Clock source is CTIMERB4 OUT. value.); 29=BUCKBLE (Clock source is BLE buck converter TON pulses. value.); 30=BUCKB (Clock source is Memory buck converter TON pulses. value.); 31=BUCKA (Clock source is CPU buck converter TON pulses. value.)
  [16] TMRB6EN — Counter/Timer B6 Enable bit.
    0=DIS (Counter/Timer B6 Disable. value.); 1=EN (Counter/Timer B6 Enable. value.)
  [12] TMRA6POL — Counter/Timer A6 output polarity.
    0=NORMAL (The polarity of the TMRPINA6 pin is the same as the timer output. value.); 1=INVERTED (The polarity of the TMRPINA6 pin is the inverse of the timer output. value.)
  [11] TMRA6CLR — Counter/Timer A6 Clear bit.
    0=RUN (Allow counter/timer A6 to run value.); 1=CLEAR (Holds counter/timer A6 at 0x0000. value.)
  [10] TMRA6IE1 — Counter/Timer A6 Interrupt Enable bit based on COMPR1.
    0=DIS (Disable counter/timer A6 from generating an interrupt based on COMPR1. value.); 1=EN (Enable counter/timer A6 to generate an interrupt based on COMPR1. value.)
  [9] TMRA6IE0 — Counter/Timer A6 Interrupt Enable bit based on COMPR0.
    0=DIS (Disable counter/timer A6 from generating an interrupt based on COMPR0. value.); 1=EN (Enable counter/timer A6 to generate an interrupt based on COMPR0. value.)
  [8:6] TMRA6FN — Counter/Timer A6 Function Select.
    0=SINGLECOUNT (Single count (output toggles and sticks). Count to CMPR0A6, stop. value.); 1=REPEATEDCOUNT (Repeated count (periodic 1-clock-cycle-wide pulses). Count to CMPR0A6, restart. value.); 2=PULSE_ONCE (Pulse once (aka one-shot). Count to CMPR0A6, assert, count to CMPR1A6, deassert, stop. value.); 3=PULSE_CONT (Pulse continously. Count to CMPR0A6, assert, count to CMPR1A6, deassert, restart. value.); 4=SINGLEPATTERN (Single pattern. value.); 5=REPEATPATTERN (Repeated pattern. value.); 6=CONTINUOUS (Continuous run (aka Free Run). Count continuously. value.); 7=ALTPWN (Alternate PWM value.)
  [5:1] TMRA6CLK — Counter/Timer A6 Clock Select.
    0=TMRPIN (Clock source is TMRPINA. value.); 1=HFRC_DIV4 (Clock source is the HFRC / 4 value.); 2=HFRC_DIV16 (Clock source is HFRC / 16 value.); 3=HFRC_DIV256 (Clock source is HFRC / 256 value.); 4=HFRC_DIV1024 (Clock source is HFRC / 1024 value.); 5=HFRC_DIV4K (Clock source is HFRC / 4096 value.); 6=XT (Clock source is the XT (uncalibrated). value.); 7=XT_DIV2 (Clock source is XT / 2 value.); 8=XT_DIV16 (Clock source is XT / 16 value.); 9=XT_DIV128 (Clock source is XT / 128 value.); 10=LFRC_DIV2 (Clock source is LFRC / 2 value.); 11=LFRC_DIV32 (Clock source is LFRC / 32 value.); 12=LFRC_DIV1K (Clock source is LFRC / 1024 value.); 13=LFRC (Clock source is LFRC value.); 14=RTC_100HZ (Clock source is 100 Hz from the current RTC oscillator. value.); 15=HCLK (Clock source is HCLK. value.); 16=XT_DIV4 (Clock source is XT / 4 value.); 17=XT_DIV8 (Clock source is XT / 8 value.); 18=XT_DIV32 (Clock source is XT / 32 value.); 20=CTMRB6 (Clock source is CTIMERB6 OUT. value.); 21=CTMRA3 (Clock source is CTIMERA3 OUT. value.); 22=CTMRB3 (Clock source is CTIMERB3 OUT. value.); 23=CTMRA7 (Clock source is CTIMERA7 OUT. value.); 24=CTMRB7 (Clock source is CTIMERB7 OUT. value.); 25=CTMRB0 (Clock source is CTIMERB0 OUT. value.); 26=CTMRB1 (Clock source is CTIMERB1 OUT. value.); 27=CTMRB2 (Clock source is CTIMERB2 OUT. value.); 28=CTMRB4 (Clock source is CTIMERB4 OUT. value.); 29=BUCKBLE (Clock source is BLE buck converter TON pulses. value.); 30=BUCKB (Clock source is Memory buck converter TON pulses. value.); 31=BUCKA (Clock source is CPU buck converter TON pulses. value.)
  [0] TMRA6EN — Counter/Timer A6 Enable bit.
    0=DIS (Counter/Timer A6 Disable. value.); 1=EN (Counter/Timer A6 Enable. value.)
